# ESW3120 register map
Vendor: Shanghai Eastsoft Microelectronics Co.,Ltd.; Series: ARMCM3; File version: 1.2
CPU: CM3 r2p1, little endian, MPU, no FPU, 4 interrupt priority bits
Registers are 32-bit, read-write, reset 0x0 unless marked. A register's access mark holds for its fields unless they carry their own. Offsets are from the block's base; [hi:lo] are bit positions; {n}, {i} and the like mark numbered series; 'fields as' and 'values as' point back to an identical list.

## MSC
Base 0x40081000
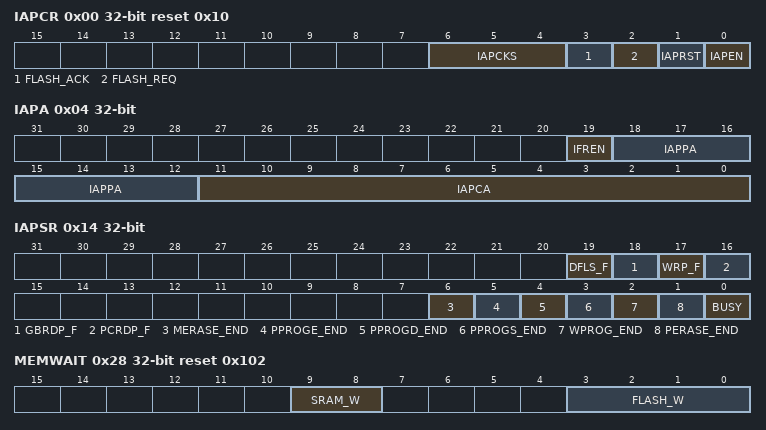
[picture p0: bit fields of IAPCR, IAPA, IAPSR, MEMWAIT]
0x00 IAPCR reset 0x10
  [6:4] IAPCKS, [3] FLASH_ACK read, [2] FLASH_REQ, [1] IAPRST clear-write1, [0] IAPEN
0x04 IAPA
  [19] IFREN, [18:12] IAPPA, [11:0] IAPCA
0x0C IAPT
  [31:0] TRIG
0x10 IAPUL reset 0x1
  [31:0] UL
0x14 IAPSR read
  [19] DFLS_F, [18] GBRDP_F, [17] WRP_F, [16] PCRDP_F, [6] MERASE_END, [5] PPROGE_END, [4] PPROGD_END, [3] PPROGS_END, [2] WPROG_END, [1] PERASE_END, [0] BUSY
0x18 IAPDL
  [31:0] DATAL
0x1C IAPDH
  [31:0] DATAH
0x28 MEMWAIT reset 0x102
  [9:8] SRAM_W, [3:0] FLASH_W
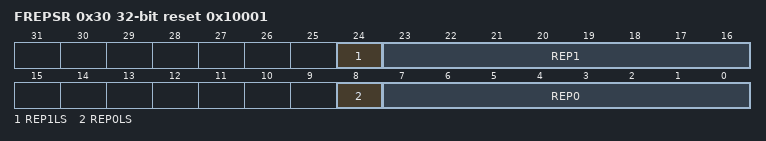
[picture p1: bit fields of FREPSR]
0x30 FREPSR read reset 0x10001
  [24] REP1LS, [23:16] REP1, [8] REP0LS, [7:0] REP0

## LP16T
Base 0x40040000
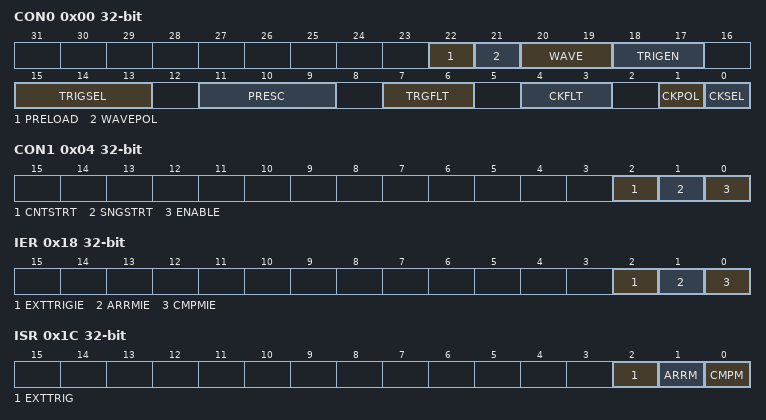
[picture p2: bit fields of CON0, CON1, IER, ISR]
0x00 CON0
  [22] PRELOAD, [21] WAVEPOL, [20:19] WAVE, [18:17] TRIGEN, [15:13] TRIGSEL, [11:9] PRESC, [7:6] TRGFLT, [4:3] CKFLT, [1] CKPOL, [0] CKSEL
0x04 CON1
  [2] CNTSTRT, [1] SNGSTRT, [0] ENABLE
0x08 ARR reset 0x1
  [15:0] ARR
0x0C CNT read
  [15:0] CNT
0x10 CMP
  [15:0] CMP
0x18 IER
  [2] EXTTRIGIE, [1] ARRMIE, [0] CMPMIE
0x1C ISR read
  [2] EXTTRIG, [1] ARRM, [0] CMPM
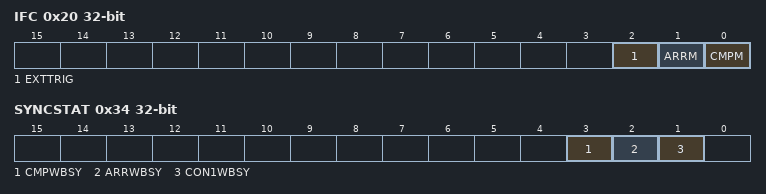
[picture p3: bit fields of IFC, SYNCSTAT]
0x20 IFC write1
  [2] EXTTRIG, [1] ARRM, [0] CMPM
0x30 UPDATE
  [0] UDIS
0x34 SYNCSTAT read
  [3] CMPWBSY, [2] ARRWBSY, [1] CON1WBSY

## KSCAN
Base 0x4000F000
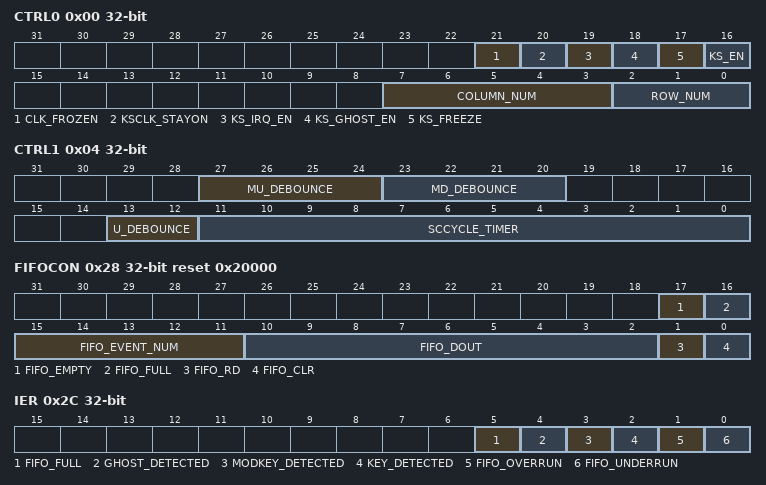
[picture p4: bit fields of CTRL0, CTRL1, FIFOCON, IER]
0x00 CTRL0
  [21] CLK_FROZEN read, [20] KSCLK_STAYON, [19] KS_IRQ_EN, [18] KS_GHOST_EN, [17] KS_FREEZE, [16] KS_EN, [7:3] COLUMN_NUM, [2:0] ROW_NUM
0x04 CTRL1
  [27:24] MU_DEBOUNCE, [23:20] MD_DEBOUNCE, [13:12] U_DEBOUNCE, [11:0] SCCYCLE_TIMER
{0x8+4i} MODKEY{i} (i=0..7)
  [7:0] KS_MODKEY{i}
0x28 FIFOCON trigger-write1 reset 0x20000
  [17] FIFO_EMPTY read, [16] FIFO_FULL read, [15:11] FIFO_EVENT_NUM read, [10:2] FIFO_DOUT read, [1] FIFO_RD, [0] FIFO_CLR
0x2C IER
  [5] FIFO_FULL, [4] GHOST_DETECTED, [3] MODKEY_DETECTED, [2] KEY_DETECTED, [1] FIFO_OVERRUN, [0] FIFO_UNDERRUN
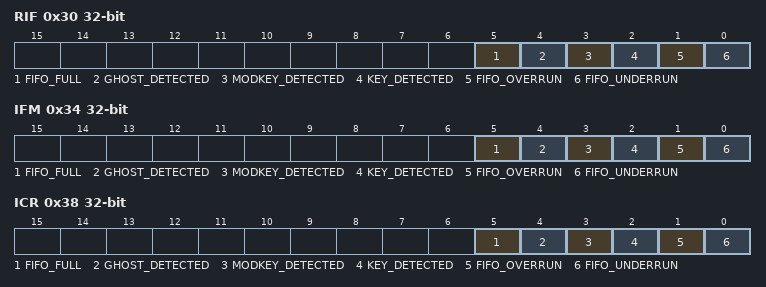
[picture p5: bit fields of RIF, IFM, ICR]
0x30 RIF read
  fields as IER
0x34 IFM read
  fields as IER
0x38 ICR write1
  fields as IER

## IWDT
Base 0x40048000
0x00 LOAD write reset 0x80000
0x04 VALUE read reset 0xFFFFFFFF
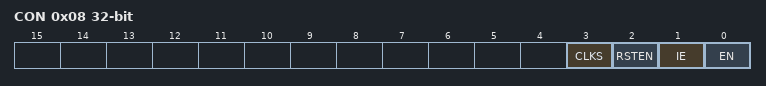
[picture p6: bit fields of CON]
0x08 CON
  [3] CLKS, [2] RSTEN, [1] IE, [0] EN
0x0C INTCLR write
0x10 RIS read
  [0] WDTIF
0x100 LOCK read reset 0x1
  [0] LOCK

## QDEC
Base 0x4000F400
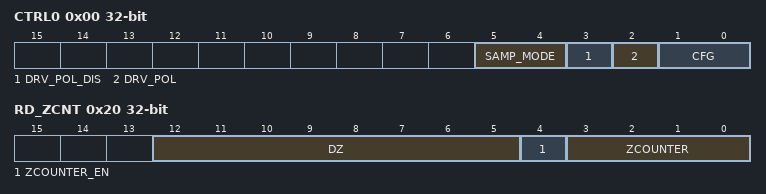
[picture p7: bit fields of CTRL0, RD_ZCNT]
0x00 CTRL0
  [5:4] SAMP_MODE, [3] DRV_POL_DIS, [2] DRV_POL, [1:0] CFG
0x20 RD_ZCNT read
  [12:5] DZ, [4] ZCOUNTER_EN, [3:0] ZCOUNTER

## GPIOEXTI
Base 0x40084300
0x00 EXTIRER
  [15:0] EXTIRER
0x08 EXTIFER
  [15:0] EXTIFER
0x10 EXTIEN
  [15:0] EXTIEN
0x18 EXTIFLAG read
  [15:0] EXTIFLAG
0x20 EXTISFR write1
  [15:0] EXTISFR
0x28 EXTICFR write1
  [15:0] EXTICFR
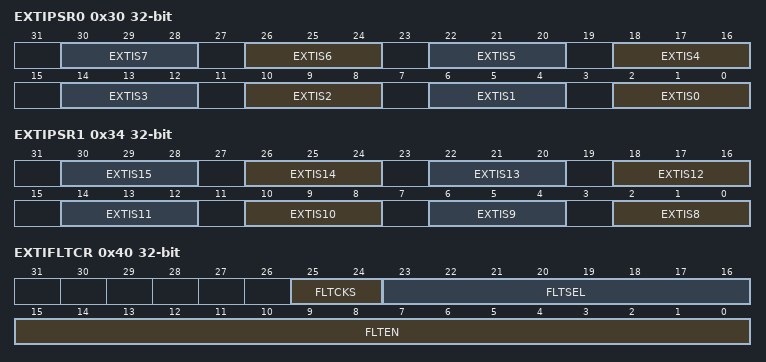
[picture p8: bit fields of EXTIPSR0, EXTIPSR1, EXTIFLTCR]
0x30 EXTIPSR0
  [4n+2:4n] EXTIS{n} (n=0..7)
0x34 EXTIPSR1
  [4n-30:4n-32] EXTIS{n} (n=8..15)
0x40 EXTIFLTCR
  [25:24] FLTCKS, [23:16] FLTSEL, [15:0] FLTEN

## GPIOA
Base 0x40084000
Same registers: GPIOB 0x40084040
0x00 DIN read
  [15:0] DIN
0x04 DOUT
  [15:0] DOUT
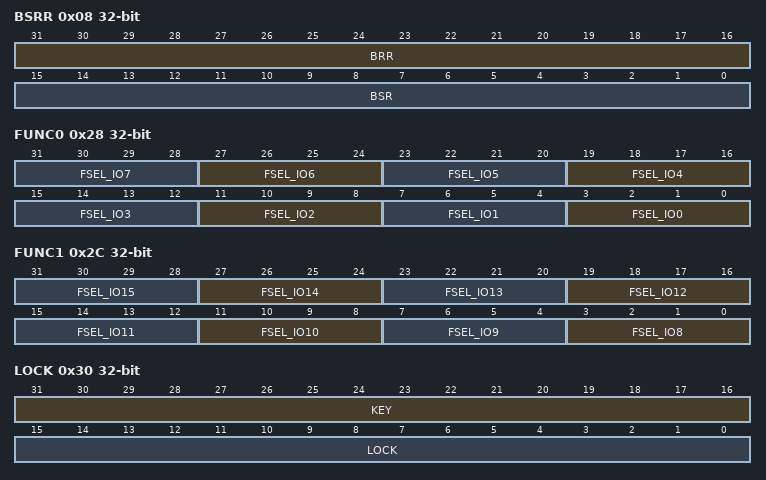
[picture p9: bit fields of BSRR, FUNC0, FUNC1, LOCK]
0x08 BSRR write
  [31:16] BRR, [15:0] BSR
0x0C BIR write
  [15:0] BIR
0x10 MODE
0x14 ODOS
0x18 PUPD
0x1C ODRV reset 0xAAAAAAAA
0x20 FLT
  [15:0] FLT
0x24 TYPE none
0x28 FUNC0
  [4n+3:4n] FSEL_IO{n} (n=0..7)
0x2C FUNC1
  [4n-29:4n-32] FSEL_IO{n} (n=8..15)
0x30 LOCK
  [31:16] KEY write, [15:0] LOCK

## ECC
Base 0x40009800
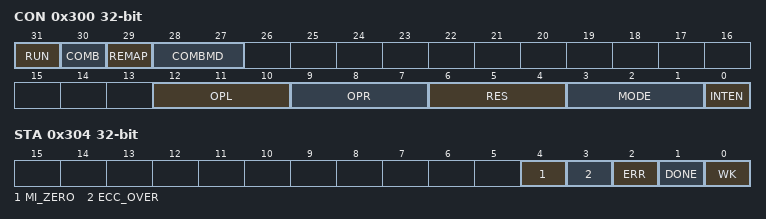
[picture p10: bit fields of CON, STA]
0x300 CON
  [31] RUN, [30] COMB write, [29] REMAP, [28:27] COMBMD, [12:10] OPL, [9:7] OPR, [6:4] RES, [3:1] MODE, [0] INTEN
0x304 STA read
  [4] MI_ZERO read-clear-write1, [3] ECC_OVER read-clear-write1, [2] ERR read-clear-write1, [1] DONE read-clear-write1, [0] WK
0x308 PARA

## DMA
Base 0x4000C000
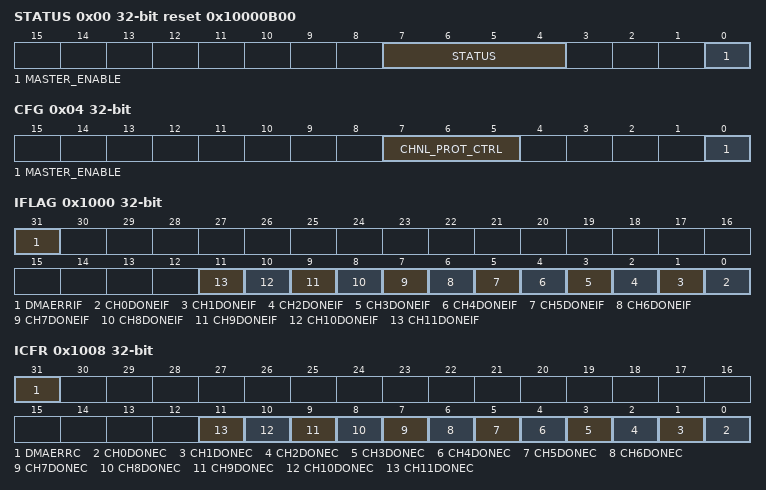
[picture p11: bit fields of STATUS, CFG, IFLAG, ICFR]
0x00 STATUS read reset 0x10000B00
  [7:4] STATUS, [0] MASTER_ENABLE
0x04 CFG write
  [7:5] CHNL_PROT_CTRL, [0] MASTER_ENABLE
0x08 CTRLBASE reset 0x4
  [31:9] CTRL_BASE_PTR
0x0C ALTCTRLBASE read reset 0x4
  [31:0] ALT_CTRL_BASE_PTR
0x10 CHWAITSTATUS read reset 0x3F
  [31:0] DMA_WAITONREQ_STATUS
0x14 CHSWREQ trigger-write1
0x18 CHUSEBURSTSET
  [31:0] CHNL_USEBURST_SET
0x1C CHUSEBURSTCLR write
  [31:0] CHNL_USEBURST_CLR
0x20 CHREQMASKSET
  [31:0] CHNL_REQ_MASK_SET
0x24 CHREQMASKCLR write
  [31:0] CHNL_REQ_MASK_CLR
0x28 CHENSET
  [31:0] CHNL_ENABLE_SET
0x2C CHENCLR write
  [31:0] CHNL_ENABLE_CLR
0x30 CHPRIALTSET
  [31:0] CHNL_PRI_ALT_SET
0x34 CHPRIALTCLR write
  [31:0] CHNL_PRI_ALT_CLR
0x38 CHPRSET
  [31:0] CHNL_PRIORITY_SET
0x3C CHPRCLR write
  [31:0] CHNL_PRIORITY_CLR
0x4C ERRCLR
  [0] ERR_CLR
0x1000 IFLAG write1
  [31] DMAERRIF read-clear-write1, [n] CH{n}DONEIF read-clear-write1 (n=0..11)
0x1008 ICFR write1
  [31] DMAERRC, [n] CH{n}DONEC (n=0..11)
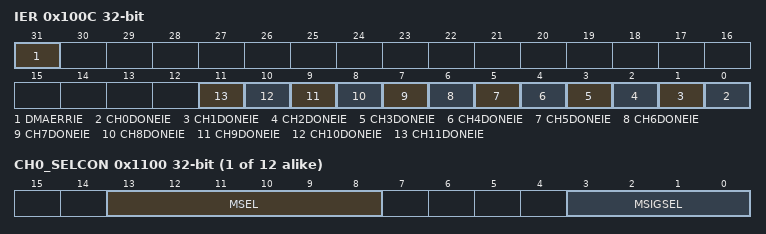
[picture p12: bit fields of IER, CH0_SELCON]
0x100C IER
  [31] DMAERRIE, [n] CH{n}DONEIE (n=0..11)
{0x1100+4i} CH{i}_SELCON (i=0..11)
  [13:8] MSEL, [3:0] MSIGSEL
